# ESP32-S3 register map
Vendor: ESPRESSIF SYSTEMS (SHANGHAI) CO., LTD.; Series: ESP32 S-Series; File version: 22
CPU: Xtensa LX7 r0p0, little endian, no MPU, FPU, 0 interrupt priority bits
Address unit: 32 bits
Registers are 32-bit, read-write, reset 0x0 unless marked. A register's access mark holds for its fields unless they carry their own. Offsets are from the block's base; [hi:lo] are bit positions; {n}, {i} and the like mark numbered series.

## APB_CTRL — APB (Advanced Peripheral Bus) Controller
Base 0x60026000
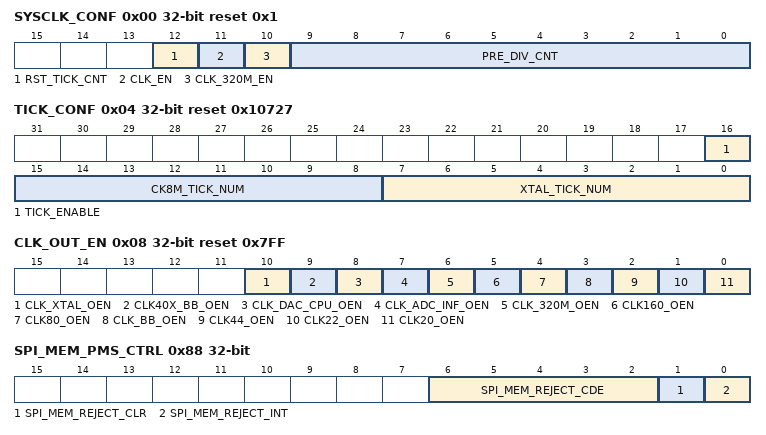
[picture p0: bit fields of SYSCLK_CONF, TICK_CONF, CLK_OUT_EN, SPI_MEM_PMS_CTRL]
0x00 SYSCLK_CONF reset 0x1 — ******* Description ***********
  [12] RST_TICK_CNT — ******* Description ***********
  [11] CLK_EN — ******* Description ***********
  [10] CLK_320M_EN — ******* Description ***********
  [9:0] PRE_DIV_CNT — ******* Description ***********
0x04 TICK_CONF reset 0x10727 — ******* Description ***********
  [16] TICK_ENABLE — ******* Description ***********
  [15:8] CK8M_TICK_NUM — ******* Description ***********
  [7:0] XTAL_TICK_NUM — ******* Description ***********
0x08 CLK_OUT_EN reset 0x7FF — ******* Description ***********
  [10] CLK_XTAL_OEN — ******* Description ***********
  [9] CLK40X_BB_OEN — ******* Description ***********
  [8] CLK_DAC_CPU_OEN — ******* Description ***********
  [7] CLK_ADC_INF_OEN — ******* Description ***********
  [6] CLK_320M_OEN — ******* Description ***********
  [5] CLK160_OEN — ******* Description ***********
  [4] CLK80_OEN — ******* Description ***********
  [3] CLK_BB_OEN — ******* Description ***********
  [2] CLK44_OEN — ******* Description ***********
  [1] CLK22_OEN — ******* Description ***********
  [0] CLK20_OEN — ******* Description ***********
0x0C WIFI_BB_CFG — ******* Description ***********
0x10 WIFI_BB_CFG_2 — ******* Description ***********
0x14 WIFI_CLK_EN reset 0xFFFCE030 — ******* Description ***********
0x18 WIFI_RST_EN — ******* Description ***********
  [31:0] WIFI_RST
0x1C HOST_INF_SEL — ******* Description ***********
  [7:0] PERI_IO_SWAP
0x20 EXT_MEM_PMS_LOCK — ******* Description ***********
  [0] EXT_MEM_PMS_LOCK
0x24 EXT_MEM_WRITEBACK_BYPASS — ******* Description ***********
  [0] WRITEBACK_BYPASS — Set 1 to bypass cache writeback request to external memory so that spi will not check its attribute.
{0x28+4i} FLASH_ACE{i}_ATTR reset 0xFF (i=0..3) — ******* Description ***********
  [8:0] FLASH_ACE{i}_ATTR
0x38 FLASH_ACE0_ADDR — ******* Description ***********
  [31:0] S
0x3C FLASH_ACE1_ADDR reset 0x10000000 — ******* Description ***********
  [31:0] S
0x40 FLASH_ACE2_ADDR reset 0x20000000 — ******* Description ***********
  [31:0] S
0x44 FLASH_ACE3_ADDR reset 0x30000000 — ******* Description ***********
  [31:0] S
{0x48+4i} FLASH_ACE{i}_SIZE reset 0x1000 (i=0..3) — ******* Description ***********
  [15:0] FLASH_ACE{i}_SIZE
{0x58+4i} SRAM_ACE{i}_ATTR reset 0xFF (i=0..3) — ******* Description ***********
  [8:0] SRAM_ACE{i}_ATTR
0x68 SRAM_ACE0_ADDR — ******* Description ***********
  [31:0] S
0x6C SRAM_ACE1_ADDR reset 0x10000000 — ******* Description ***********
  [31:0] S
0x70 SRAM_ACE2_ADDR reset 0x20000000 — ******* Description ***********
  [31:0] S
0x74 SRAM_ACE3_ADDR reset 0x30000000 — ******* Description ***********
  [31:0] S
{0x78+4i} SRAM_ACE{i}_SIZE reset 0x1000 (i=0..3) — ******* Description ***********
  [15:0] SRAM_ACE{i}_SIZE
0x88 SPI_MEM_PMS_CTRL access per field — ******* Description ***********
  [6:2] SPI_MEM_REJECT_CDE ro — ******* Description ***********
  [1] SPI_MEM_REJECT_CLR wo — ******* Description ***********
  [0] SPI_MEM_REJECT_INT ro — ******* Description ***********
0x8C SPI_MEM_REJECT_ADDR ro — ******* Description ***********
0x90 SDIO_CTRL — ******* Description ***********
  [0] SDIO_WIN_ACCESS_EN
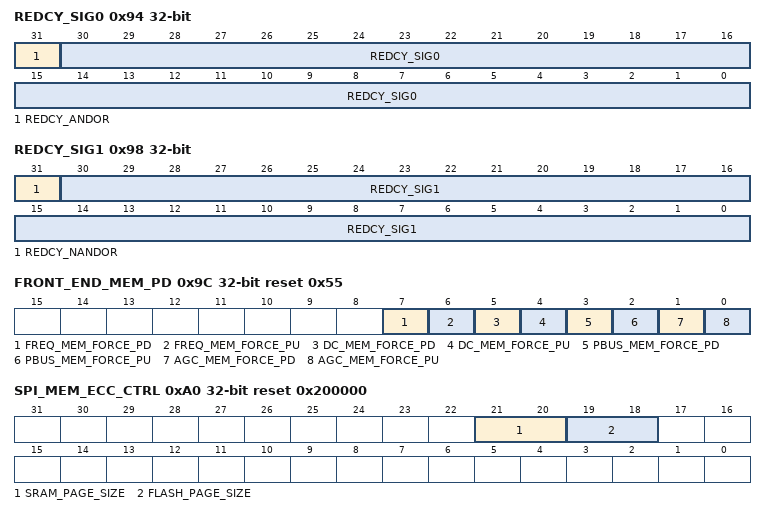
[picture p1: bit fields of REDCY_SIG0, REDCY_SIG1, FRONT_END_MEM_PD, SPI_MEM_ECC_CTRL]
0x94 REDCY_SIG0 access per field — ******* Description ***********
  [31] REDCY_ANDOR ro — ******* Description ***********
  [30:0] REDCY_SIG0 rw — ******* Description ***********
0x98 REDCY_SIG1 access per field — ******* Description ***********
  [31] REDCY_NANDOR ro — ******* Description ***********
  [30:0] REDCY_SIG1 rw — ******* Description ***********
0x9C FRONT_END_MEM_PD reset 0x55 — ******* Description ***********
  [7] FREQ_MEM_FORCE_PD — ******* Description ***********
  [6] FREQ_MEM_FORCE_PU — ******* Description ***********
  [5] DC_MEM_FORCE_PD — ******* Description ***********
  [4] DC_MEM_FORCE_PU — ******* Description ***********
  [3] PBUS_MEM_FORCE_PD — ******* Description ***********
  [2] PBUS_MEM_FORCE_PU — ******* Description ***********
  [1] AGC_MEM_FORCE_PD — ******* Description ***********
  [0] AGC_MEM_FORCE_PU — ******* Description ***********
0xA0 SPI_MEM_ECC_CTRL reset 0x200000 — ******* Description ***********
  [21:20] SRAM_PAGE_SIZE — Set the page size of the used MSPI external RAM. 0: 256 bytes. 1: 512 bytes. 2: 1024 bytes. 3: 2048 bytes.
  [19:18] FLASH_PAGE_SIZE — Set the page size of the used MSPI flash. 0: 256 bytes. 1: 512 bytes. 2: 1024 bytes. 3: 2048 bytes.
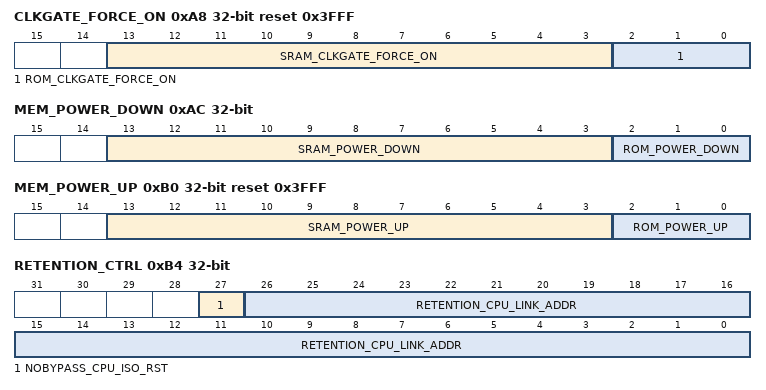
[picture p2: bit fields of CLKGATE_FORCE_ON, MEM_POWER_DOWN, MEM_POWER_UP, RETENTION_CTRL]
0xA8 CLKGATE_FORCE_ON reset 0x3FFF — ******* Description ***********
  [13:3] SRAM_CLKGATE_FORCE_ON — ******* Description ***********
  [2:0] ROM_CLKGATE_FORCE_ON — ******* Description ***********
0xAC MEM_POWER_DOWN — ******* Description ***********
  [13:3] SRAM_POWER_DOWN — ******* Description ***********
  [2:0] ROM_POWER_DOWN — ******* Description ***********
0xB0 MEM_POWER_UP reset 0x3FFF — ******* Description ***********
  [13:3] SRAM_POWER_UP — ******* Description ***********
  [2:0] ROM_POWER_UP — ******* Description ***********
0xB4 RETENTION_CTRL — ******* Description ***********
  [27] NOBYPASS_CPU_ISO_RST — ******* Description ***********
  [26:0] RETENTION_CPU_LINK_ADDR — ******* Description ***********
0xB8 RETENTION_CTRL1 — ******* Description ***********
  [26:0] RETENTION_TAG_LINK_ADDR
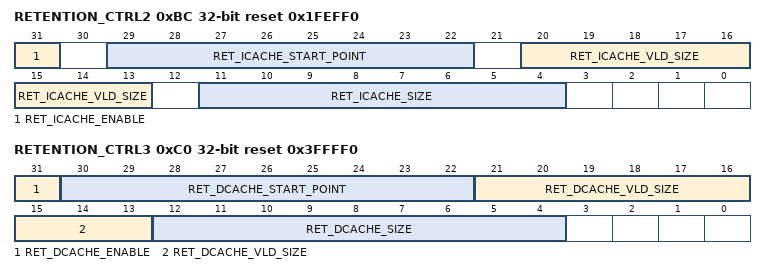
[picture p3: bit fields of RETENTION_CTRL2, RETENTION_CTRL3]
0xBC RETENTION_CTRL2 reset 0x1FEFF0 — ******* Description ***********
  [31] RET_ICACHE_ENABLE — ******* Description ***********
  [29:22] RET_ICACHE_START_POINT — ******* Description ***********
  [20:13] RET_ICACHE_VLD_SIZE — ******* Description ***********
  [11:4] RET_ICACHE_SIZE — ******* Description ***********
0xC0 RETENTION_CTRL3 reset 0x3FFFF0 — ******* Description ***********
  [31] RET_DCACHE_ENABLE — ******* Description ***********
  [30:22] RET_DCACHE_START_POINT — ******* Description ***********
  [21:13] RET_DCACHE_VLD_SIZE — ******* Description ***********
  [12:4] RET_DCACHE_SIZE — ******* Description ***********
0xC4 RETENTION_CTRL4 reset 0xFFFFFFFF — ******* Description ***********
  [31:0] RETENTION_INV_CFG
0xC8 RETENTION_CTRL5 — ******* Description ***********
  [0] RETENTION_DISABLE
0x3FC DATE reset 0x2101150 — ******* Description ***********
  [31:0] DATE — Version control
